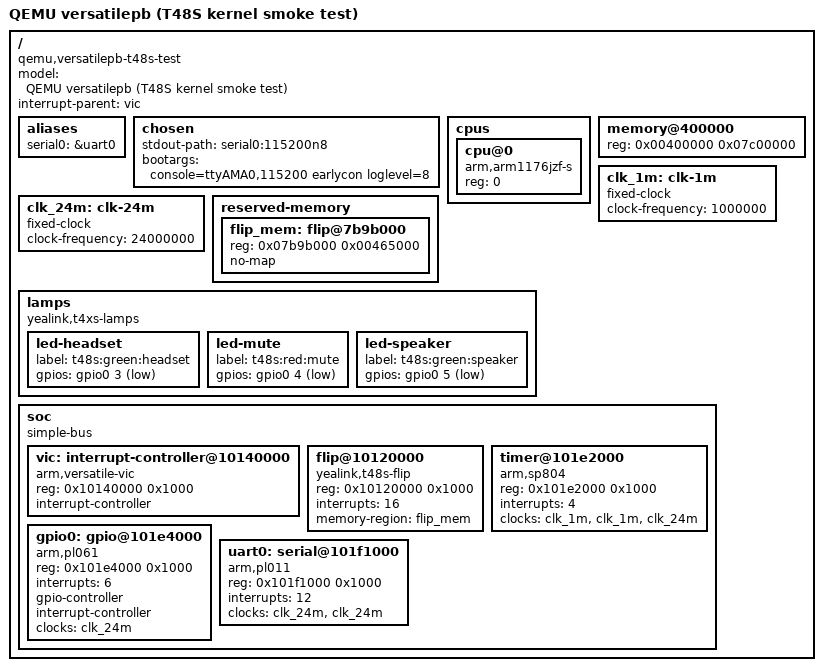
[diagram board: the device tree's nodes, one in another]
// SPDX-License-Identifier: GPL-2.0
/*
 * Not a phone: QEMU's "versatilepb" machine with an ARM1176, described just
 * far enough to smoke-test the T48S kernel configuration and root filesystem
 * on a PC (kernel6/qemu-test.sh). It has the same kinds of parts as the
 * BCM11188 (a VIC, SP804 timers, a PL011) at other addresses, and a PL061 for
 * the lamps' pins. Its RAM starts
 * at 0, but only what the phone has is declared (from 0x00400000), so the
 * kernel is placed as on the phone.
 */
/dts-v1/;

/ {
	#address-cells = <1>;
	#size-cells = <1>;
	model = "QEMU versatilepb (T48S kernel smoke test)";
	compatible = "qemu,versatilepb-t48s-test";
	interrupt-parent = <&vic>;

	aliases {
		serial0 = &uart0;
	};

	chosen {
		stdout-path = "serial0:115200n8";
		bootargs = "console=ttyAMA0,115200 earlycon loglevel=8";
	};

	cpus {
		#address-cells = <1>;
		#size-cells = <0>;

		cpu@0 {
			device_type = "cpu";
			compatible = "arm,arm1176jzf-s";
			reg = <0>;
		};
	};

	memory@400000 {
		device_type = "memory";
		reg = <0x00400000 0x07c00000>;
	};

	clk_1m: clk-1m {
		compatible = "fixed-clock";
		#clock-cells = <0>;
		clock-frequency = <1000000>;
	};

	clk_24m: clk-24m {
		compatible = "fixed-clock";
		#clock-cells = <0>;
		clock-frequency = <24000000>;
	};

	/* room for frames, where the phone has it, for drivers/t48s_flip.c */
	reserved-memory {
		#address-cells = <1>;
		#size-cells = <1>;
		ranges;

		flip_mem: flip@7b9b000 {
			reg = <0x07b9b000 0x00465000>;
			no-map;
		};
	};

	/* three lamps on pins that go nowhere: the timer and the LED devices are real */
	lamps {
		compatible = "yealink,t4xs-lamps";

		led-headset {
			label = "t48s:green:headset";
			gpios = <&gpio0 3 1>;
		};

		led-mute {
			label = "t48s:red:mute";
			gpios = <&gpio0 4 1>;
		};

		led-speaker {
			label = "t48s:green:speaker";
			gpios = <&gpio0 5 1>;
		};
	};

	soc {
		compatible = "simple-bus";
		#address-cells = <1>;
		#size-cells = <1>;
		ranges;

		vic: interrupt-controller@10140000 {
			compatible = "arm,versatile-vic";
			reg = <0x10140000 0x1000>;
			interrupt-controller;
			#interrupt-cells = <1>;
		};

		/* the board's PL110, which nothing has switched on: the driver loads and waits */
		flip@10120000 {
			compatible = "yealink,t48s-flip";
			reg = <0x10120000 0x1000>;
			interrupts = <16>;
			memory-region = <&flip_mem>;
		};

		timer@101e2000 {
			compatible = "arm,sp804";
			reg = <0x101e2000 0x1000>;
			interrupts = <4>;
			clocks = <&clk_1m>, <&clk_1m>, <&clk_24m>;
			clock-names = "timer1", "timer2", "apb_pclk";
		};

		/* the board's first PL061, for drivers/t48s_lamps.c to switch */
		gpio0: gpio@101e4000 {
			compatible = "arm,pl061", "arm,primecell";
			reg = <0x101e4000 0x1000>;
			interrupts = <6>;
			gpio-controller;
			#gpio-cells = <2>;
			interrupt-controller;
			#interrupt-cells = <2>;
			clocks = <&clk_24m>;
			clock-names = "apb_pclk";
		};

		uart0: serial@101f1000 {
			compatible = "arm,pl011", "arm,primecell";
			reg = <0x101f1000 0x1000>;
			interrupts = <12>;
			clocks = <&clk_24m>, <&clk_24m>;
			clock-names = "uartclk", "apb_pclk";
		};
	};
};
